# R5FSS0 register map
Vendor: Texas Instruments
Peripheral module from a debugger description file (folder J7VCL).
Registers are 32-bit, read-only, reset 0x0 unless marked. A register's access mark holds for its fields unless they carry their own. Offsets are as the file gives them; lines under a group give offsets from that group; [hi:lo] are bit positions; {n}, {i} and the like mark numbered series; 'fields as' and 'values as' point back to an identical list; <NAME> marks a mode.

## R5FSS0
0x00 R5FSS_DISABLE_CR access per field — Return to the . This register contains config bits to enable or disable change requests added to the IP.
  [0] COMBINE_TCM_LOCKSTEP_MODE rw — This bit disables the CR logic to combine TCM in lockstep mode
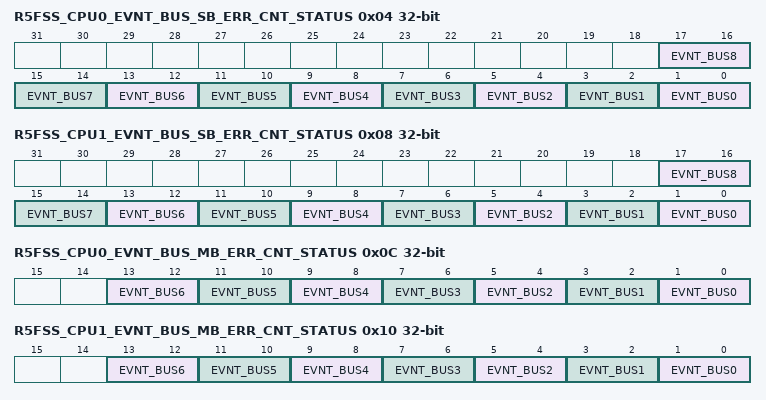
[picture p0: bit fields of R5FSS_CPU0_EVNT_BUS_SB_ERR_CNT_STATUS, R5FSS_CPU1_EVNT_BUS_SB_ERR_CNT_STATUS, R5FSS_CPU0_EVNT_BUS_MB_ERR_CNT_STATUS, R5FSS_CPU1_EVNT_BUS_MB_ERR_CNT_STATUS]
0x04 R5FSS_CPU0_EVNT_BUS_SB_ERR_CNT_STATUS — Return to the . Status bits showing the R5FSS CPU0 EVNT BUS single-bit error counters.
  [2n+1:2n] EVNT_BUS{n} (n=0..8) — Status bits showing the R5FSS CPU0 EVNT {n} single-bit error counter
0x08 R5FSS_CPU1_EVNT_BUS_SB_ERR_CNT_STATUS — Return to the . Status bits showing the R5FSS CPU1 EVNT BUS single-bit error counters.
  [2n+1:2n] EVNT_BUS{n} (n=0..8) — Status bits showing the R5FSS CPU1 EVNT {n} single-bit error counter
0x0C R5FSS_CPU0_EVNT_BUS_MB_ERR_CNT_STATUS — Return to the . Status bits showing the R5FSS CPU0 EVNT BUS multi-bit error counters.
  [2n+1:2n] EVNT_BUS{n} (n=0..6) — Status bits showing the R5FSS CPU0 EVNT {n} multi-bit error counter
0x10 R5FSS_CPU1_EVNT_BUS_MB_ERR_CNT_STATUS — Return to the . Status bits showing the R5FSS CPU1 EVNT BUS multi-bit error counters.
  [2n+1:2n] EVNT_BUS{n} (n=0..6) — Status bits showing the R5FSS CPU1 EVNT {n} multi-bit error counter
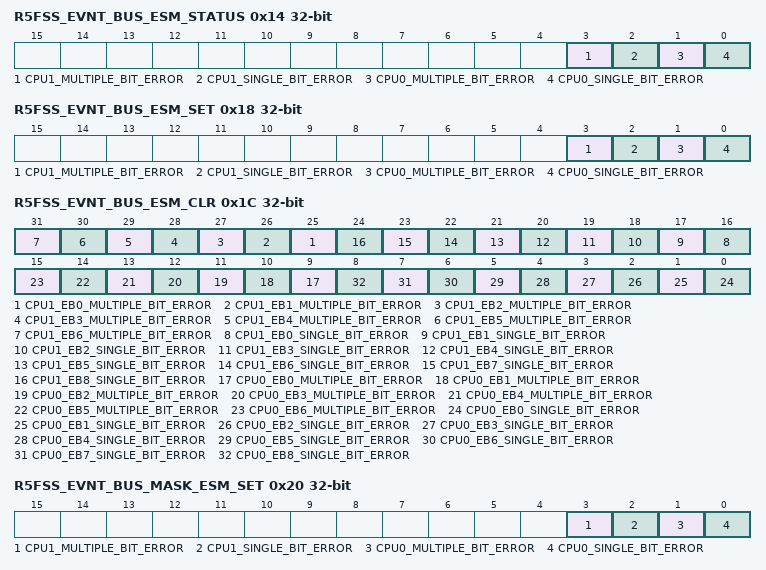
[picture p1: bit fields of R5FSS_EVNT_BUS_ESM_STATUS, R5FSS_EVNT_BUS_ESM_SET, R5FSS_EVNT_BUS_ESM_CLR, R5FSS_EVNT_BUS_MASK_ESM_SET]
0x14 R5FSS_EVNT_BUS_ESM_STATUS — Return to the . ESM status bits for the R5FSS EVNT BUS.
  [3] CPU1_MULTIPLE_BIT_ERROR — ESM status of CPU1 multi-bit errors on EVNT BUS
  [2] CPU1_SINGLE_BIT_ERROR — ESM status of CPU1 single-bit errors on EVNT BUS
  [1] CPU0_MULTIPLE_BIT_ERROR — ESM status of CPU0 multi-bit errors on EVNT BUS
  [0] CPU0_SINGLE_BIT_ERROR — ESM status of CPU0 single-bit errors on EVNT BUS
0x18 R5FSS_EVNT_BUS_ESM_SET access not given — Return to the . Set the R5FSS EVNT BUS ESM events.
  [3] CPU1_MULTIPLE_BIT_ERROR — Set CPU1 multi-bit errors ESM event (access RW1S)
  [2] CPU1_SINGLE_BIT_ERROR — Set CPU1 single-bit errors ESM event (access RW1S)
  [1] CPU0_MULTIPLE_BIT_ERROR — Set CPU0 multi-bit error ESM event (access RW1S)
  [0] CPU0_SINGLE_BIT_ERROR — Set CPU0 single-bit error ESM event (access RW1S)
0x1C R5FSS_EVNT_BUS_ESM_CLR rw — Return to the . RESET the R5FSS EVNT BUS ESM events.
  [n+25] CPU1_EB{n}_MULTIPLE_BIT_ERROR (n=0..6) — Decrement CPU1 EVNT BUS {n+25} multi-bit error counter
  [n+16] CPU1_EB{n}_SINGLE_BIT_ERROR (n=0..8) — Decrement CPU1 EVNT BUS {n+16} single-bit error counter
  [n+9] CPU0_EB{n}_MULTIPLE_BIT_ERROR (n=0..6) — Decrement CPU0 EVNT BUS {n+9} multi-bit error counter
  [n] CPU0_EB{n}_SINGLE_BIT_ERROR (n=0..8) — Decrement CPU0 EVNT BUS {n} single-bit error counter
0x20 R5FSS_EVNT_BUS_MASK_ESM_SET access not given — Return to the . Mask the R5FSS EVNT BUS ESM events.
  [3] CPU1_MULTIPLE_BIT_ERROR — Mask CPU1 multi-bit errors ESM event (access RW1S)
  [2] CPU1_SINGLE_BIT_ERROR — Mask CPU1 single-bit errors ESM event (access RW1S)
  [1] CPU0_MULTIPLE_BIT_ERROR — Mask CPU0 multi-bit error ESM event (access RW1S)
  [0] CPU0_SINGLE_BIT_ERROR — Mask CPU0 single-bit error ESM event (access RW1S)
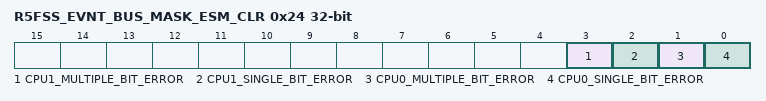
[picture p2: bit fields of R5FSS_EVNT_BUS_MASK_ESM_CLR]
0x24 R5FSS_EVNT_BUS_MASK_ESM_CLR access not given — Return to the . Unmask the R5FSS EVNT BUS ESM events.
  [3] CPU1_MULTIPLE_BIT_ERROR — Unmask CPU1 multi-bit errors ESM event (access RW1C)
  [2] CPU1_SINGLE_BIT_ERROR — Unmask CPU1 single-bit errors ESM event (access RW1C)
  [1] CPU0_MULTIPLE_BIT_ERROR — Unmask CPU0 multi-bit error ESM event (access RW1C)
  [0] CPU0_SINGLE_BIT_ERROR — Unmask CPU0 single-bit error ESM event (access RW1C)
